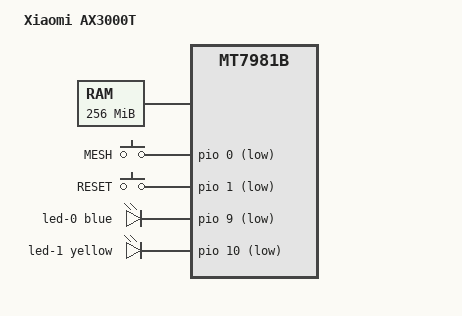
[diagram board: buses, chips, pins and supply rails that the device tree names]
// SPDX-License-Identifier: GPL-2.0-only OR MIT

/dts-v1/;
#include <dt-bindings/input/input.h>
#include <dt-bindings/gpio/gpio.h>
#include <dt-bindings/leds/common.h>

#include "mt7981b.dtsi"

/ {
	compatible = "xiaomi,ax3000t", "mediatek,mt7981b";
	model = "Xiaomi AX3000T";

	memory@40000000 {
		reg = <0 0x40000000 0 0x10000000>;
		device_type = "memory";
	};

	keys {
		compatible = "gpio-keys";

		key-mesh {
			label = "MESH";
			gpios = <&pio 0 GPIO_ACTIVE_LOW>;
			linux,code = <BTN_9>;
			linux,input-type = <EV_SW>;
		};

		key-reset {
			label = "RESET";
			gpios = <&pio 1 GPIO_ACTIVE_LOW>;
			linux,code = <KEY_RESTART>;
		};
	};

	leds {
		compatible = "gpio-leds";

		led-0 {
			color = <LED_COLOR_ID_BLUE>;
			function = LED_FUNCTION_STATUS;
			gpios = <&pio 9 GPIO_ACTIVE_LOW>;
		};

		led-1 {
			color = <LED_COLOR_ID_YELLOW>;
			function = LED_FUNCTION_STATUS;
			gpios = <&pio 10 GPIO_ACTIVE_LOW>;
		};
	};
};
